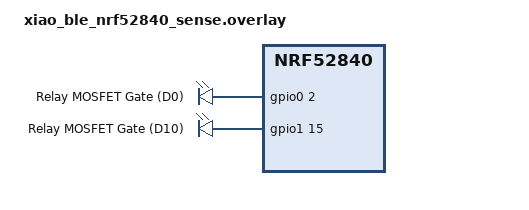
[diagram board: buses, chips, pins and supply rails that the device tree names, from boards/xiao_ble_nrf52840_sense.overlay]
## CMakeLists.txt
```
cmake_minimum_required(VERSION 3.20.0)

find_package(Zephyr REQUIRED HINTS $ENV{ZEPHYR_BASE})
project(fip-remote-button)

target_sources(app PRIVATE
    src/main.c
    src/ble/ble_relay_service.c
    src/led/led.c
    src/led/led_hal.c
    src/relay/relay.c
    src/relay/relay_hal.c
    src/timer/relay_timer.c
    src/watchdog/watchdog.c
)

target_include_directories(app PRIVATE src)
```

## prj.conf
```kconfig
# GPIO for relay control and status LED
CONFIG_GPIO=y

# Disable NCS Partition Manager (Adafruit bootloader needs code at 0x27000)
CONFIG_PARTITION_MANAGER_ENABLED=n

# USB CDC for serial console (development/debug)
CONFIG_USB_DEVICE_STACK=y
CONFIG_SERIAL=y
CONFIG_CONSOLE=y
CONFIG_UART_CONSOLE=y
CONFIG_USB_CDC_ACM=y
CONFIG_UART_LINE_CTRL=y

# Logging
CONFIG_LOG=y
CONFIG_LOG_DEFAULT_LEVEL=3
CONFIG_LOG_BACKEND_UART=y

# BLE
CONFIG_BT=y
CONFIG_BT_PERIPHERAL=y
CONFIG_BT_DEVICE_NAME="FIP-relay"
CONFIG_BT_DEVICE_APPEARANCE=0
CONFIG_BT_MAX_CONN=1

# BLE connection parameters (power optimization)
CONFIG_BT_PERIPHERAL_PREF_MIN_INT=80
CONFIG_BT_PERIPHERAL_PREF_MAX_INT=400
CONFIG_BT_PERIPHERAL_PREF_LATENCY=4
CONFIG_BT_PERIPHERAL_PREF_TIMEOUT=1000

# Stack size for BLE workqueue
CONFIG_SYSTEM_WORKQUEUE_STACK_SIZE=2048

# Hardware watchdog (fail-safe: resets MCU if firmware hangs)
CONFIG_WATCHDOG=y

# Power management (idle sleep between events)
CONFIG_PM=y
```

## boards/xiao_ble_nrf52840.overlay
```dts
/ {
    aliases {
        led0 = &relay0;
    };

    relays {
        compatible = "gpio-leds";
        relay0: relay_0 {
            gpios = <&gpio0 2 GPIO_ACTIVE_HIGH>;
            label = "Relay MOSFET Gate";
        };
    };
};
```

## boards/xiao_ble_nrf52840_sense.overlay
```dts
/ {
    aliases {
        relay0 = &relay_out0;
        relay1 = &relay_out1;
    };

    relays {
        compatible = "gpio-leds";
        relay_out0: relay_0 {
            gpios = <&gpio0 2 GPIO_ACTIVE_HIGH>;
            label = "Relay MOSFET Gate (D0)";
        };
        relay_out1: relay_1 {
            gpios = <&gpio1 15 GPIO_ACTIVE_HIGH>;
            label = "Relay MOSFET Gate (D10)";
        };
    };
};
```

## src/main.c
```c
#include <zephyr/bluetooth/bluetooth.h>
#include <zephyr/drivers/gpio.h>
#include <zephyr/kernel.h>
#include <zephyr/logging/log.h>
#include <zephyr/usb/usb_device.h>

#include "ble/ble_relay_service.h"
#include "led/led.h"
#include "relay/relay.h"
#include "timer/relay_timer.h"
#include "watchdog/watchdog.h"

LOG_MODULE_REGISTER(main, LOG_LEVEL_INF);

int main(void)
{
    usb_enable(NULL);
    k_msleep(1000);

    LOG_INF("=== XIAO-RELAY BOOT ===");

    int err = led_init();
    if (err)
        LOG_ERR("LED init failed: %d", err);

    err = relay_init();
    if (err)
    {
        LOG_ERR("Relay init failed: %d", err);
        while (1)
        {
            led_show_error();
            k_msleep(100);
        }
    }
    LOG_INF("Relay initialized (OFF)");

    err = ble_relay_service_init();
    if (err)
    {
        LOG_ERR("BLE init failed: %d", err);
        while (1)
        {
            led_show_error();
            k_msleep(100);
        }
    }

    err = watchdog_init();
    if (err)
        LOG_WRN("Watchdog disabled: %d", err);

    LOG_INF("Advertising as 'FIP-relay'");

    uint8_t tick_count = 0;

    while (1)
    {
        watchdog_feed();
        led_update(relay_get_state(), ble_relay_is_connected());

        tick_count++;
        if (tick_count >= 2)
        {
            tick_count = 0;
            relay_timer_tick();
            if (relay_timer_is_running() && ble_relay_is_connected())
                ble_relay_timer_remaining_notify();
        }

        k_msleep(500);
    }

    return 0;
}
```
